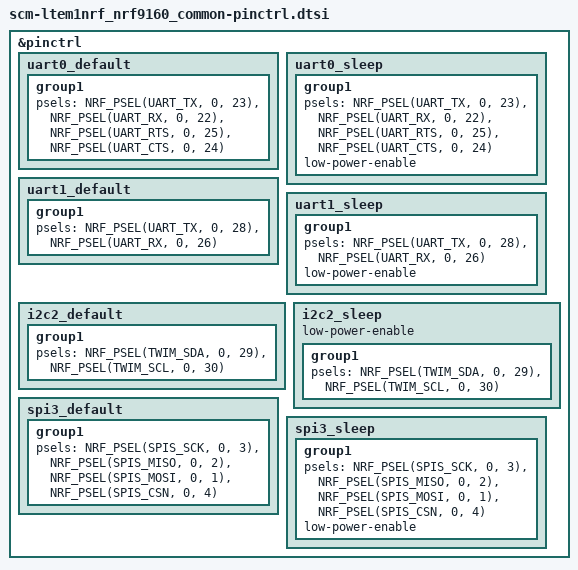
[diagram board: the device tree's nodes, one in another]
/*
 * Copyright (c) 2022 Nordic Semiconductor
 * SPDX-License-Identifier: Apache-2.0
 */

&pinctrl {
	uart0_default: uart0_default {
		group1 {
			psels = <NRF_PSEL(UART_TX, 0, 23)>,
				<NRF_PSEL(UART_RX, 0, 22)>,
				<NRF_PSEL(UART_RTS, 0, 25)>,
				<NRF_PSEL(UART_CTS, 0, 24)>;
		};
	};

	uart0_sleep: uart0_sleep {
		group1 {
			psels = <NRF_PSEL(UART_TX, 0, 23)>,
				<NRF_PSEL(UART_RX, 0, 22)>,
				<NRF_PSEL(UART_RTS, 0, 25)>,
				<NRF_PSEL(UART_CTS, 0, 24)>;
			low-power-enable;
		};
	};

	uart1_default: uart1_default {
		group1 {
			psels = <NRF_PSEL(UART_TX, 0, 28)>,
				<NRF_PSEL(UART_RX, 0, 26)>;
		};
	};

	uart1_sleep: uart1_sleep {
		group1 {
			psels = <NRF_PSEL(UART_TX, 0, 28)>,
				<NRF_PSEL(UART_RX, 0, 26)>;
			low-power-enable;
		};
	};

	i2c2_default: i2c2_default {
		group1 {
			psels = <NRF_PSEL(TWIM_SDA, 0, 29)>,
				<NRF_PSEL(TWIM_SCL, 0, 30)>;
		};
	};

	i2c2_sleep: i2c2_sleep {
		group1 {
			psels = <NRF_PSEL(TWIM_SDA, 0, 29)>,
				<NRF_PSEL(TWIM_SCL, 0, 30)>;
		};
		low-power-enable;
	};

	spi3_default: spi3_default {
		group1 {
			psels = <NRF_PSEL(SPIS_SCK, 0, 3)>,
				<NRF_PSEL(SPIS_MISO, 0, 2)>,
				<NRF_PSEL(SPIS_MOSI, 0, 1)>,
				<NRF_PSEL(SPIS_CSN, 0, 4)>;
		};
	};

	spi3_sleep: spi3_sleep {
		group1 {
			psels = <NRF_PSEL(SPIS_SCK, 0, 3)>,
				<NRF_PSEL(SPIS_MISO, 0, 2)>,
				<NRF_PSEL(SPIS_MOSI, 0, 1)>,
				<NRF_PSEL(SPIS_CSN, 0, 4)>;
			low-power-enable;
		};
	};
};
